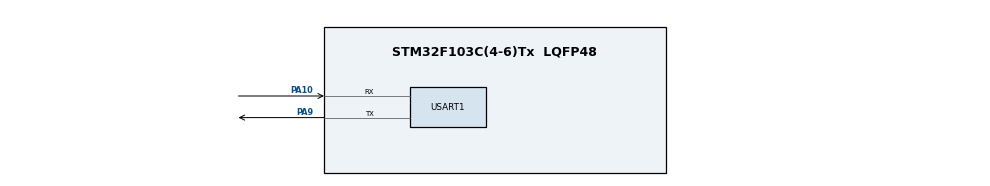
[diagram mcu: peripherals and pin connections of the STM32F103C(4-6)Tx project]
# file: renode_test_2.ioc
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Mcu.Family=STM32F1
Mcu.Name=STM32F103C(4-6)Tx
Mcu.Package=LQFP48
NVIC.PriorityGroup=NVIC_PRIORITYGROUP_4
PA10.Mode=Asynchronous
PA10.Signal=USART1_RX
PA9.Mode=Asynchronous
PA9.Signal=USART1_TX
ProjectManager.HeapSize=0x200
ProjectManager.StackSize=0x400
ProjectManager.TargetToolchain=STM32CubeIDE
RCC.APB1Freq_Value=8000000
RCC.APB2Freq_Value=8000000
USART1.VirtualMode=VM_ASYNC
board=custom

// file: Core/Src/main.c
/* USER CODE BEGIN Header */
/**
  ******************************************************************************
  * @file           : main.c
  * @brief          : Main program body
  ******************************************************************************
  * @attention
  *
  * Copyright (c) 2022 STMicroelectronics.
  * All rights reserved.
  *
  * This software is licensed under terms that can be found in the LICENSE file
  * in the root directory of this software component.
  * If no LICENSE file comes with this software, it is provided AS-IS.
  *
  ******************************************************************************
  */
/* USER CODE END Header */
#include "main.h"
#include "usart.h"
#include "gpio.h"

void SystemClock_Config(void);

int main(void)
{

  /* MCU Configuration--------------------------------------------------------*/

  /* Reset of all peripherals, Initializes the Flash interface and the Systick. */
  HAL_Init();

  /* Configure the system clock */
  SystemClock_Config();

  /* Initialize all configured peripherals */
  MX_GPIO_Init();
  MX_USART1_UART_Init();
  /* USER CODE BEGIN 2 */
  uint8_t tx_data[6] = "test\n";
  uint8_t rx_data[1];

  /* USER CODE END 2 */

  /* Infinite loop */
  while (1)
  {

    HAL_UART_Receive(&huart1, rx_data, 1, 100000);
    switch (rx_data[0]) {
    case 0x01: HAL_UART_Transmit(&huart1, "one\n\0", 6, 100); break;
    case 0x02: HAL_UART_Transmit(&huart1, "two\n\0", 6, 100); break;
    case 0x03: HAL_UART_Transmit(&huart1, "thr\n\0", 6, 100); break;
    case 0x04: HAL_UART_Transmit(&huart1, "fou\n\0", 6, 100); break;
    default:
	HAL_UART_Transmit(&huart1, "666\n\0", 6, 100); break;
    }
    HAL_Delay(1000);
  }
}

void SystemClock_Config(void)
{
  RCC_OscInitTypeDef RCC_OscInitStruct = {0};
  RCC_ClkInitTypeDef RCC_ClkInitStruct = {0};

  /** Initializes the RCC Oscillators according to the specified parameters
  * in the RCC_OscInitTypeDef structure.
  */
  RCC_OscInitStruct.OscillatorType = RCC_OSCILLATORTYPE_HSI;
  RCC_OscInitStruct.HSIState = RCC_HSI_ON;
  RCC_OscInitStruct.HSICalibrationValue = RCC_HSICALIBRATION_DEFAULT;
  RCC_OscInitStruct.PLL.PLLState = RCC_PLL_NONE;
  if (HAL_RCC_OscConfig(&RCC_OscInitStruct) != HAL_OK)
  {
    Error_Handler();
  }

  /** Initializes the CPU, AHB and APB buses clocks
  */
  RCC_ClkInitStruct.ClockType = RCC_CLOCKTYPE_HCLK|RCC_CLOCKTYPE_SYSCLK
                              |RCC_CLOCKTYPE_PCLK1|RCC_CLOCKTYPE_PCLK2;
  RCC_ClkInitStruct.SYSCLKSource = RCC_SYSCLKSOURCE_HSI;
  RCC_ClkInitStruct.AHBCLKDivider = RCC_SYSCLK_DIV1;
  RCC_ClkInitStruct.APB1CLKDivider = RCC_HCLK_DIV1;
  RCC_ClkInitStruct.APB2CLKDivider = RCC_HCLK_DIV1;

  if (HAL_RCC_ClockConfig(&RCC_ClkInitStruct, FLASH_LATENCY_0) != HAL_OK)
  {
    Error_Handler();
  }
}

void Error_Handler(void)
{
  __disable_irq();
  while (1)
  {
  }
}
